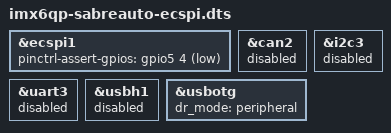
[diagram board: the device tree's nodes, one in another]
// SPDX-License-Identifier: GPL-2.0
//
// Copyright (C) 2015 Freescale Semiconductor, Inc.


#include "imx6qp-sabreauto.dts"

&ecspi1 {
	pinctrl-assert-gpios = <&gpio5 4 GPIO_ACTIVE_LOW>;
	status = "okay";
};

&can2 {
	/* max7310_c on i2c3 is gone */
	status = "disabled";
};

&i2c3 {
	/* pin conflict with ecspi1 */
	status = "disabled";
};

&uart3 {
	/* the uart3 depends on the i2c3, so disable it too. */
	status = "disabled";
};

&usbh1 {
	/* max7310_b on i2c3 is gone */
	status = "disabled";
};

&usbotg {
	/* max7310_c on i2c3 is gone */
	status = "okay";
	dr_mode = "peripheral";
};
